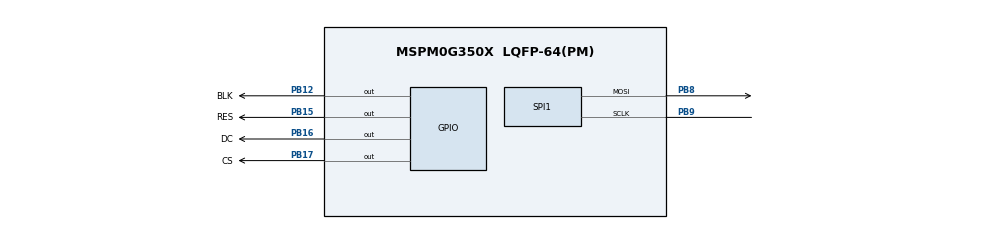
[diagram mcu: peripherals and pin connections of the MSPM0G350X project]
/**
 *
 * @cliArgs --device "MSPM0G350X" --part "Default" --package "LQFP-64(PM)" --product "mspm0_sdk@2.10.00.04"
 * @versions {"tool":"1.28.0+4696"}
 */

/**
 * Import the modules used in this configuration.
 */
const GPIO   = scripting.addModule("/ti/driverlib/GPIO", {}, false);
const GPIO1  = GPIO.addInstance();
const SPI    = scripting.addModule("/ti/driverlib/SPI", {}, false);
const SPI1   = SPI.addInstance();
const SYSCTL = scripting.addModule("/ti/driverlib/SYSCTL");

/**
 * Write custom configuration values to the imported modules.
 */
GPIO1.$name                          = "GPIO_LCD";
GPIO1.port                           = "PORTB";
GPIO1.associatedPins.create(4);
GPIO1.associatedPins[0].$name        = "DC";
GPIO1.associatedPins[0].pin.$assign  = "PB16";
GPIO1.associatedPins[1].$name        = "RES";
GPIO1.associatedPins[1].initialValue = "SET";
GPIO1.associatedPins[1].pin.$assign  = "PB15";
GPIO1.associatedPins[2].$name        = "CS";
GPIO1.associatedPins[2].initialValue = "SET";
GPIO1.associatedPins[2].pin.$assign  = "PB17";
GPIO1.associatedPins[3].$name        = "BLK";
GPIO1.associatedPins[3].pin.$assign  = "PB12";

const Board = scripting.addModule("/ti/driverlib/Board", {}, false);

SPI1.$name                      = "SPI_0";
SPI1.frameFormat                = "MOTO3";
SPI1.direction                  = "PICO";
SPI1.sclkPinConfig.$name        = "ti_driverlib_gpio_GPIOPinGeneric0";
SPI1.mosiPinConfig.$name        = "ti_driverlib_gpio_GPIOPinGeneric1";
SPI1.peripheral.$assign         = "SPI1";
SPI1.peripheral.sclkPin.$assign = "PB9";
SPI1.peripheral.mosiPin.$assign = "PB8";

SYSCTL.forceDefaultClkConfig = true;

/**
 * Pinmux solution for unlocked pins/peripherals. This ensures that minor changes to the automatic solver in a future
 * version of the tool will not impact the pinmux you originally saw.  These lines can be completely deleted in order to
 * re-solve from scratch.
 */
Board.peripheral.$suggestSolution          = "DEBUGSS";
Board.peripheral.swclkPin.$suggestSolution = "PA20";
Board.peripheral.swdioPin.$suggestSolution = "PA19";
SYSCTL.peripheral.$suggestSolution         = "SYSCTL";
